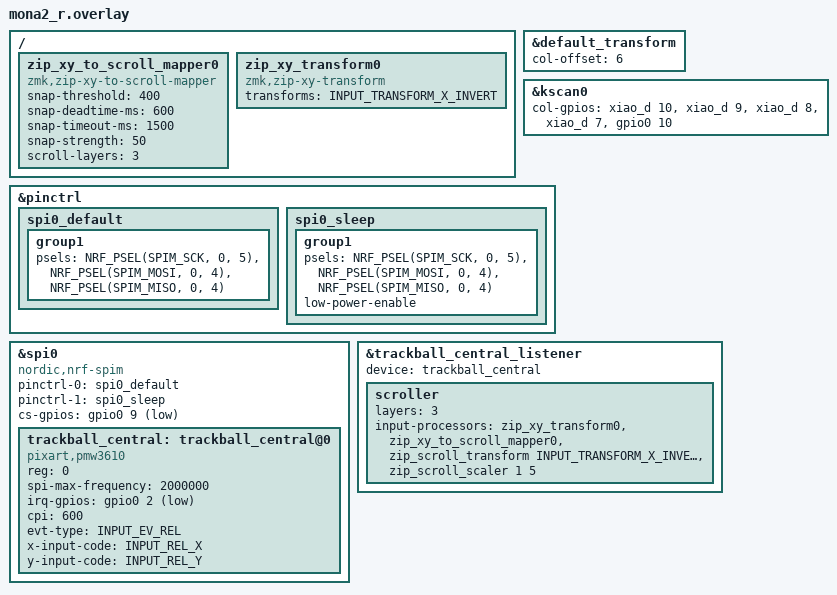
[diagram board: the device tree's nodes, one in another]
#include "mona2.dtsi"
#include <input/processors.dtsi>
#include <zephyr/dt-bindings/input/input-event-codes.h>

&default_transform {
    col-offset = <6>;
};

&kscan0 {
        col-gpios
            = <&xiao_d 10 GPIO_ACTIVE_HIGH>
            , <&xiao_d 9 GPIO_ACTIVE_HIGH> 
            , <&xiao_d 8 GPIO_ACTIVE_HIGH> 
            , <&xiao_d 7 GPIO_ACTIVE_HIGH> 
            , <&gpio0 10 GPIO_ACTIVE_HIGH>
            ;
};

&pinctrl {
    spi0_default: spi0_default {    // 通常時(SPI通信中)のピン構成
        group1 {
            psels = <NRF_PSEL(SPIM_SCK, 0, 5)>, // P0.05 (SCLK)
                <NRF_PSEL(SPIM_MOSI, 0, 4)>,    // P0.04 (SDIO: MOSI/MISO兼用)
                <NRF_PSEL(SPIM_MISO, 0, 4)>;
        };
    };

    spi0_sleep: spi0_sleep {        // スリープ時のピン構成(省電力)
        group1 {
            psels = <NRF_PSEL(SPIM_SCK, 0, 5)>,
                <NRF_PSEL(SPIM_MOSI, 0, 4)>,
                <NRF_PSEL(SPIM_MISO, 0, 4)>;
            low-power-enable;
        };
    };
};

&spi0 {
    status = "okay";
    compatible = "nordic,nrf-spim";
    pinctrl-0 = <&spi0_default>;
    pinctrl-1 = <&spi0_sleep>;
    pinctrl-names = "default", "sleep";
    cs-gpios = <&gpio0 9 GPIO_ACTIVE_LOW>;  // P0.09 (CS)

    trackball_central: trackball_central@0 {
        status = "okay";
        compatible = "pixart,pmw3610";
        reg = <0>;
        spi-max-frequency = <2000000>;
        irq-gpios = <&gpio0 2 (GPIO_ACTIVE_LOW | GPIO_PULL_UP)>; // P0.02 (MOTION)
        cpi = <600>;
        // swap-xy;
        // invert-x; // COROPIT版ではコメントアウトを外す
        // invert-y; // COROPIT版ではコメントアウトを外す
        evt-type = <INPUT_EV_REL>;
        x-input-code = <INPUT_REL_X>;
        y-input-code = <INPUT_REL_Y>;
    };
};

/* ===== スナップ付きスクロール用プロセッサ ===== */
 / {
    /* XY→スクロール化＋スナップ（層3でのみ有効） */
    zip_xy_to_scroll_mapper0: zip_xy_to_scroll_mapper0 {
        compatible = "zmk,zip-xy-to-scroll-mapper";
        #input-processor-cells = <0>;          /* ★ phandle-with-args 要件を満たす */

        snap-threshold = <400>;
        snap-deadtime-ms = <600>;
        snap-timeout-ms = <1500>;
        snap-strength = <50>;

        scroll-layers = <3>;
    };

    /* 前処理（X反転など） */
    zip_xy_transform0: zip_xy_transform0 {
        compatible = "zmk,zip-xy-transform";
        #input-processor-cells = <0>;          /* ★ こちらも追加 */
        transforms = <INPUT_TRANSFORM_X_INVERT>;
        /* 例: transforms = <INPUT_TRANSFORM_Y_INVERT>; */
        /* 例: transforms = <INPUT_TRANSFORM_Y_INVERT INPUT_TRANSFORM_XY_SWAP>; */
    };
};

/* 入力リスナー：前処理 → スナップ付きスクロール → 仕上げ */
&trackball_central_listener {
    status = "okay";
    device = <&trackball_central>;

    scroller {
        layers = <3>;
        input-processors =
            <&zip_xy_transform0>,                       /* 前処理（X反転） */
            <&zip_xy_to_scroll_mapper0>,                /* 自動スナップ付きスクロール化 */
            <&zip_scroll_transform INPUT_TRANSFORM_X_INVERT>, /* 水平スクロール反転 */
            <&zip_scroll_scaler 1 5>;                   /* スクロール量スケール（実装依存） */
    };
};
